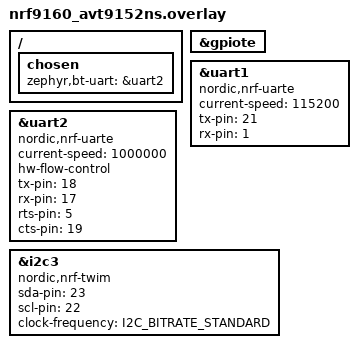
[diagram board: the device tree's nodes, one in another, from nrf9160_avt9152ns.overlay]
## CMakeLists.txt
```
#
# Copyright (c) 2019 Nordic Semiconductor
#
# SPDX-License-Identifier: LicenseRef-BSD-5-Clause-Nordic
#

cmake_minimum_required(VERSION 3.13.1)

list(APPEND mcuboot_OVERLAY_CONFIG
  "${CMAKE_CURRENT_SOURCE_DIR}/child_mcuboot.conf"
  )

set(spm_CONF_FILE
  prj.conf
  ${CMAKE_CURRENT_SOURCE_DIR}/child_secure_partition_manager.conf
  )

find_package(Zephyr REQUIRED HINTS $ENV{ZEPHYR_BASE})
project(demo_IoTConnect)



# NORDIC SDK APP START
target_sources(app PRIVATE src/main.c)
target_sources(app PRIVATE src/slm_at_host.c)
target_sources(app PRIVATE src/slm_util.c)
target_sources(app PRIVATE src/slm_at_gps.c)
target_sources(app PRIVATE src/orientation_tap_detector.c)
target_sources(app PRIVATE src/pir_detector.c)
target_sources(app PRIVATE src/rotation_detector.c)
target_sources(app PRIVATE src/env_sensors.c)
target_sources(app PRIVATE src/gps.c)
zephyr_library_sources_ifdef(CONFIG_SUPL_CLIENT_LIB src/supl_support.c)

target_link_libraries(app PRIVATE ${CMAKE_CURRENT_SOURCE_DIR}/IoTConnect/libiotconnect.a)

zephyr_include_directories(IoTConnect)
# NORDIC SDK APP END
```

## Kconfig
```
#
# Copyright (c) 2019 Nordic Semiconductor
#
# SPDX-License-Identifier: LicenseRef-BSD-5-Clause-Nordic
#

menu "Demo IoTConnect"

config DEMO_AT_MAX_PARAM
	int "Max number of parameters in AT command"
	default 8
	
config DEMO_ENVIRONMENT_DATA_SEND_INTERVAL
	int "Interval in seconds for sending environment data"
	default 60
	help
	  How often to send environment sensor data.
	  If the GPS is active, sensor data will not be sent before it is
	  stopped. The unit is seconds.


#
# A-GPS
#
config DEMO_SUPL_SERVER
	string "SUPL server"
	default "supl.google.com"

config DEMO_SUPL_SERVER_PORT
	int "SUPL server port"
	default 7276

module = DEMO_IOTCONNECT
module-str = demo
source "${ZEPHYR_BASE}/subsys/logging/Kconfig.template.log_config"

endmenu

menu "Zephyr Kernel"
source "Kconfig.zephyr"
endmenu
```

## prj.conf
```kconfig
# Demo IoTConnect

CONFIG_DEMO_IOTCONNECT_LOG_LEVEL_DBG=y
CONFIG_MCUBOOT_IMAGE_VERSION="1.0.2"

#<major>*1000000 + <minor>*1000 + <build>
CONFIG_FW_INFO_FIRMWARE_VERSION=1000002

# Stacks and heaps
CONFIG_MAIN_STACK_SIZE=8192
CONFIG_HEAP_MEM_POOL_SIZE=16384
CONFIG_SYSTEM_WORKQUEUE_STACK_SIZE=2048


# Device power management
CONFIG_DEVICE_POWER_MANAGEMENT=y

# Sensors I2C
CONFIG_I2C=y
CONFIG_I2C_NRFX=y

# UART for slm_at_host
CONFIG_UART_NRFX=y
CONFIG_NRFX_UARTE=y
CONFIG_NRFX_UARTE0=y
CONFIG_UART_0_INTERRUPT_DRIVEN=n
CONFIG_UART_ASYNC_API=y
CONFIG_UART_0_ASYNC=y
CONFIG_UART_0_NRF_HW_ASYNC=y
CONFIG_UART_0_NRF_HW_ASYNC_TIMER=1
CONFIG_NRFX_TIMER=y
CONFIG_NRFX_TIMER1=y

# C Library
CONFIG_NEWLIB_LIBC=y
CONFIG_NEWLIB_LIBC_FLOAT_PRINTF=y

# File Systems
CONFIG_NVS=y
CONFIG_PM_PARTITION_SIZE_NVS_STORAGE=0x4000
CONFIG_MPU_ALLOW_FLASH_WRITE=y
CONFIG_NVS_LOG_LEVEL_OFF=y

# Debugging Options
CONFIG_ASSERT=y
#CONFIG_DEBUG_OPTIMIZATIONS=y

# Logging
CONFIG_LOG=y
CONFIG_LOG_PRINTK=y
CONFIG_LOG_IMMEDIATE=y
#CONFIG_LOG_BUFFER_SIZE=4096


# Networking
CONFIG_NETWORKING=y
CONFIG_NET_NATIVE=n
CONFIG_NET_SOCKETS=y
CONFIG_NET_SOCKETS_OFFLOAD=y # using \nrf\lib\bsdlib\nrf91_sockets.c

# BSD Library for nrf91
CONFIG_BSD_LIBRARY=y
CONFIG_BSD_LIBRARY_TRACE_ENABLED=n

# AT Command driver
CONFIG_AT_CMD=y                   # needed by slm_at_host

CONFIG_AT_NOTIF=y                 # needed by slm_at_host
CONFIG_AT_CMD_PARSER=y            # needed by slm_at_host

CONFIG_SUPL_CLIENT_LIB=y          # needed for aGPS


# Modem key management
CONFIG_MODEM_KEY_MGMT=y

# LTE link control
CONFIG_LTE_LINK_CONTROL=y
CONFIG_LTE_AUTO_INIT_AND_CONNECT=n
CONFIG_LTE_NETWORK_MODE_LTE_M_GPS=y         # doesnt matter as lte network to use will be based on setting stored in nvs
CONFIG_LTE_LEGACY_PCO_MODE=y                # extended PCO may not be supported by the network
CONFIG_LTE_NETWORK_USE_FALLBACK=n
#CONFIG_LTE_LINK_CONTROL_LOG_LEVEL_DBG=y

# MQTT
CONFIG_MQTT_LIB=y
CONFIG_MQTT_LIB_TLS=y

# External libraries
CONFIG_CJSON_LIB=y

# add fota support
CONFIG_BOOTLOADER_MCUBOOT=y       # to enable mcuboot
CONFIG_REBOOT=y                   # to enable sys_reboot() to be able to automatically reset to boot to the updated image
CONFIG_FOTA_DOWNLOAD=y            # to include FOTA library
CONFIG_FOTA_DOWNLOAD_PROGRESS_EVT=y # for the caller to be updated of download progress
CONFIG_DOWNLOAD_CLIENT=y          # needed by FOTA_DOWNLOAD
#CONFIG_DOWNLOAD_CLIENT_LOG_LEVEL_DBG=y
CONFIG_DFU_TARGET=y               # needed by FOTA_DOWNLOAD
CONFIG_DFU_TARGET_MODEM=y         # enabled by default with DFU_TARGET=y
CONFIG_DFU_TARGET_MCUBOOT=y       # enabled by default with DFU_TARGET=y given all needed modules are enabled
CONFIG_IMG_MANAGER=y              # needed by DFU_TARGET_MCUBOOT
CONFIG_IMG_ERASE_PROGRESSIVELY=y  # needed by DFU_TARGET_MCUBOOT
CONFIG_MCUBOOT_IMG_MANAGER=y      # enabled by IMG_MANAGER=y
CONFIG_FLASH_MAP=y                # needed by MCUBOOT_IMG_MANAGER
CONFIG_FLASH=y                    # needed by FLASH_MAP for FLASH_HAS_DRIVER_ENABLED

# copy config from http_application_update example
CONFIG_DOWNLOAD_CLIENT_STACK_SIZE=4096

# <account>.blob.core.windows.net is closing the connection without responding on https GET partial request of 2kB
CONFIG_DOWNLOAD_CLIENT_HTTP_FRAG_SIZE_1024=y

# copy config from azure_fota example
CONFIG_DOWNLOAD_CLIENT_BUF_SIZE=2300

# Enable Bluetooth stack and libraries
CONFIG_BT=y
#CONFIG_BT_DEBUG_LOG=y
CONFIG_BT_DEVICE_NAME="AVT9152"
CONFIG_BT_H4=y
#CONFIG_BT_UART_ON_DEV_NAME="UART_2" is set through board files with chosen { zephyr,bt-uart=&uart2; }
CONFIG_BT_WAIT_NOP=y
CONFIG_BT_BROADCASTER=y
#CONFIG_UART_2_NRF_UARTE=y is set through board files with &uart2 { compatible = "nordic,nrf-uarte"; }
CONFIG_UART_2_INTERRUPT_DRIVEN=y
#CONFIG_UART_2_NRF_FLOW_CONTROL=y is set through board files with &uart2 { hw-flow-control; }
CONFIG_BT_HCI_VS=y
```

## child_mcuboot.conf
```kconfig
#
# Copyright (c) 2020 Nordic Semiconductor ASA
#
# SPDX-License-Identifier: LicenseRef-BSD-5-Clause-Nordic
#

CONFIG_USE_SEGGER_RTT=y
CONFIG_RTT_CONSOLE=y
CONFIG_UART_CONSOLE=n

CONFIG_SIZE_OPTIMIZATIONS=y

# MCUBoot settings
CONFIG_BOOT_MAX_IMG_SECTORS=256

# MCUboot serial recovery
CONFIG_MCUBOOT_SERIAL=y
CONFIG_BOOT_SERIAL_DETECT_PORT="GPIO_0"
CONFIG_BOOT_SERIAL_DETECT_PIN=21
CONFIG_BOOT_SERIAL_DETECT_PIN_VAL=0

CONFIG_BOOT_SIGNATURE_TYPE_RSA=y
CONFIG_BOOT_SIGNATURE_KEY_FILE="root-rsa-2048.pem"
```

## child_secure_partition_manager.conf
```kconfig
#
# Copyright (c) 2019 Nordic Semiconductor ASA
#
# SPDX-License-Identifier: LicenseRef-BSD-5-Clause-Nordic
#

# Set UARTE2 as non-secure, used for bluetooth controller
CONFIG_SPM_NRF_UARTE2_NS=y

# Set REGULATORS as non-secure, used for sleep/wakeup
CONFIG_SPM_NRF_REGULATORS_NS=y

# Enable below for power saving
CONFIG_SERIAL=n
CONFIG_CONSOLE=n
CONFIG_UART_CONSOLE=n
CONFIG_LOG=n
CONFIG_LOG_BACKEND_UART=n
```

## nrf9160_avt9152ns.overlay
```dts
/* SPDX-License-Identifier: Apache-2.0 */

/ {
	chosen {
		zephyr,bt-uart = &uart2;
	};
};

&gpiote {
	status = "okay";
};

&uart1 {
	compatible = "nordic,nrf-uarte";
	current-speed = <115200>;
	status = "okay";
	tx-pin = <21>;
	rx-pin = <1>; 
};

&uart2 {
	compatible = "nordic,nrf-uarte";
	current-speed = <1000000>;
	hw-flow-control;
	status = "okay";
	tx-pin = <18>;
	rx-pin = <17>;
	rts-pin = <5>;
	cts-pin = <19>;
};

&i2c3 {
	compatible = "nordic,nrf-twim";
	status = "okay";
	sda-pin = <23>;
	scl-pin = <22>;
	clock-frequency = <I2C_BITRATE_STANDARD>;
};
```

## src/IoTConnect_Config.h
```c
#ifndef IOTCONNECT_CONFIG_H
#define IOTCONNECT_CONFIG_H

#define CONFIG_IOTCONNECT_DISCOVERY_SEC_TAG         623
#define CONFIG_IOTCONNECT_MQTT_SEC_TAG              624

#define CONFIG_IOTCONNECT_POLL_TIMEOUT_MS           500

#define CONFIG_IOTCONNECT_SYSTEM_TIME_UPDATE        (60 * 60)  // in seconds

/* IoTConnect credential configuration */

/* comment out CONFIG_IOTCONNECT_DEVICE_UNIQUE_ID to use device IMEI as its unique id */
#if 0
#define CONFIG_IOTCONNECT_DEVICE_UNIQUE_ID          "avt9152testdev0001"
#endif
#define CONFIG_IOTCONNECT_DEVICE_CP_ID              "149847e8f3ab4f11a90878bfa7da9922"
#define CONFIG_IOTCONNECT_DEVICE_ENV                "avnet"


#endif /* IOTCONNECT_CONFIG_H */
```

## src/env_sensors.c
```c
/*
 * Copyright (c) 2020 Avnet Asia Pte. Ltd.
 *
 * SPDX-License-Identifier: LicenseRef-BSD-3-Clause
 */

#include <zephyr.h>
#include <device.h>
#include <drivers/i2c.h>
#include "env_sensors_regs.h"
#include "env_sensors.h"


#define SENSORS_TASK_STACK_SIZE     KB(1)
#define SENSORS_TASK_PRIORITY       K_LOWEST_APPLICATION_THREAD_PRIO


#define SENSORS_DATA_UPDATE_INTERVAL_S      1

#include <logging/log.h>
LOG_MODULE_REGISTER(env_sensors, LOG_LEVEL_INF);


K_THREAD_STACK_DEFINE(sensors_task_stack_area, SENSORS_TASK_STACK_SIZE);
K_SEM_DEFINE(m_sens_data_sem, 1, 1);
K_SEM_DEFINE(m_evt_data_sem, 1, 1);

struct k_thread sensors_task_thread_data;
k_tid_t m_sensors_task_tid;

static const struct device *sensors_i2c_dev = NULL;
static env_sensors_data_t m_sens_data;
static bool m_task_stop;
static bool m_task_stopped;


static bool i2c_read_reg(const struct device *dev, uint8_t slave_addr, uint8_t reg, uint8_t *p_reg_val){

    struct i2c_msg msgs[2];

    msgs[0].buf = &reg;
    msgs[0].len = 1U;
    msgs[0].flags = I2C_MSG_WRITE;

    msgs[1].buf = p_reg_val;
    msgs[1].len = 1U;
    msgs[1].flags = I2C_MSG_READ | I2C_MSG_STOP;

    return i2c_transfer(dev, msgs, 2, slave_addr);
}

static bool i2c_read_regs(const struct device *dev, uint8_t slave_addr, uint8_t start_reg, uint8_t *p_reg_vals, uint32_t regs_to_read){

    struct i2c_msg msgs[2];

    msgs[0].buf = &start_reg;
    msgs[0].len = 1U;
    msgs[0].flags = I2C_MSG_WRITE;

    msgs[1].buf = p_reg_vals;
    msgs[1].len = regs_to_read;
    msgs[1].flags = I2C_MSG_READ | I2C_MSG_STOP;

    return i2c_transfer(dev, msgs, 2, slave_addr);
}

static int i2c_write_reg(const struct device *dev, uint8_t slave_addr, uint8_t reg, uint8_t reg_val){

    struct i2c_msg msgs[1];
    uint8_t payload[2];

    payload[0] = reg;
    payload[1] = reg_val;

    msgs[0].buf = payload;
    msgs[0].len = 2U;
    msgs[0].flags = I2C_MSG_WRITE | I2C_MSG_STOP;

    return i2c_transfer(dev, msgs, 1, slave_addr);
}

static void reset_sensors_data(){

    m_sens_data.pressure = 0.0;
    m_sens_data.temperature = 0.0;
    m_sens_data.humidity = 0.0;
    m_sens_data.illumination = 0;
}

static void read_sensors_data(){
    
    int err_code;
    uint8_t rx[5];
    env_sensors_data_t sd;

    memset(&sd, 0, sizeof(sd));
     
    /* Read Pressure and temperature */
    // trigger one-shot 
    err_code = i2c_write_reg(sensors_i2c_dev, LPS22HB_7BIT_ADDR, LPS22HB_REG_CTRL2, LPS22HB_REG_CTRL2_ONE_SHOT | LPS22HB_REG_CTRL2_ADD_INC_EN);
    if (err_code != 0){
        LOG_ERR("U4 LPS22HB Pressure+Temp ONE_SHOT failed 0x%0x.", err_code);
        goto read_TE_2314277_1;
    }
    do
    {
        err_code = i2c_read_reg(sensors_i2c_dev, LPS22HB_7BIT_ADDR, LPS22HB_REG_CTRL2, &rx[0]);
        if (err_code != 0){
            LOG_ERR("U4 LPS22HB Pressure+Temp read CTRL2 failed 0x%0x.", err_code);
            goto read_TE_2314277_1;
        }
    } while ((rx[0] & LPS22HB_REG_CTRL2_ONE_SHOT) != 0);

    // status register T_DA=1 P_DA=1
    err_code = i2c_read_reg(sensors_i2c_dev, LPS22HB_7BIT_ADDR, LPS22HB_REG_STATUS, &rx[0]);
    if (err_code != 0){
        LOG_ERR("U4 LPS22HB Pressure+Temp read STATUS failed 0x%0x.", err_code);
        goto read_TE_2314277_1;
    }
    if ((rx[0] & 0x03) != 0x03){
        LOG_ERR("U4 LPS22HB Pressure+Temp T_DA & P_DA expected to be set.");
        goto read_TE_2314277_1;
    }

    // read data
    err_code = i2c_read_regs(sensors_i2c_dev, LPS22HB_7BIT_ADDR, LPS22HB_REG_PRESS_OUT_XL, rx, 5);
    if (err_code != 0){
        LOG_ERR("U4 LPS22HB Pressure+Temp read data failed 0x%0x.", err_code);
        goto read_TE_2314277_1;
    }
    {
        uint32_t pres;
        uint16_t temp;
        pres = ((uint32_t) rx[0]) |
               (((uint32_t) rx[1]) << 8) |
               (((uint32_t) rx[2]) << 16);
        pres <<= 8;
        temp = ((uint16_t) rx[3]) |
               (((uint16_t) rx[4]) << 8);
        // Dividing by 256 because signed integer can't be shifted by 8
        sd.pressure    = *((int32_t *) &pres) / 256.0 / 4096.0;
        sd.temperature = *((int16_t *) &temp) / 100.0;
    }
    
read_TE_2314277_1:

    /* Read humidity and illuminiation */

    err_code = i2c_write_reg(sensors_i2c_dev, TE_2314277_1_7BIT_ADDR, TE_2314277_1_REG_SCAN_START_BYTE,
                            TE_2314277_1_REG_SCAN_HUMIDITY_BITMASK | TE_2314277_1_REG_SCAN_LIGHT_BITMASK);
    if (err_code != 0){
        LOG_ERR("U5 2314277-1 Ambimate write SCAN_START_BYTE failed 0x%0x.", err_code);
        return;
    }
    // wait until measurement is complete
    do {
        k_sleep(SYS_TIMEOUT_MS(10));
        err_code = i2c_read_reg(sensors_i2c_dev, TE_2314277_1_7BIT_ADDR, TE_2314277_1_REG_SCAN_START_BYTE, &rx[0]);
    } while ((err_code == 0) && (rx[0] > 0));
    if (err_code != 0){
        LOG_ERR("U5 2314277-1 Ambimate read SCAN_START_BYTE failed 0x%0x.", err_code);
        return;
    }
    err_code = i2c_read_regs(sensors_i2c_dev, TE_2314277_1_7BIT_ADDR, TE_2314277_1_REG_HUMIDITY_H, rx, 4);
    if (err_code != 0){
        LOG_ERR("U5 2314277-1 Ambimate read measurement data failed 0x%0x.", err_code);
        return;
    }

    // convert the raw data to engineering units
    sd.humidity = (rx[0] * 256.0 + rx[1]) / 10.0;
    sd.illumination = (rx[2] * 256 + rx[3]);

    //transfer
    k_sem_take(&m_sens_data_sem, SYS_TIMEOUT_MS(SYS_FOREVER_MS));
    memcpy(&m_sens_data, &sd, sizeof(env_sensors_data_t));
    k_sem_give(&m_sens_data_sem);

}

static void sensors_task(void *p1, void *p2, void *p3){

    m_task_stopped = false;

    LOG_DBG(">>");

    reset_sensors_data();

    while(!m_task_stop){

        read_sensors_data();

        k_sleep(SYS_TIMEOUT_MS(SENSORS_DATA_UPDATE_INTERVAL_S * MSEC_PER_SEC));

    }
    
    m_task_stopped = true;

    LOG_DBG("<<");
}

bool env_sensors_start(void){

    if(!m_task_stopped){
        return false;
    }
    
    m_task_stop = false;

    m_sensors_task_tid = k_thread_create(&sensors_task_thread_data, sensors_task_stack_area,
                                 K_THREAD_STACK_SIZEOF(sensors_task_stack_area),
                                 sensors_task,
                                 NULL, NULL, NULL,
                                 SENSORS_TASK_PRIORITY, 0, K_NO_WAIT);

    return true;
}

bool env_sensors_stop(void){

    uint32_t start_time;

    m_task_stop = true;

    start_time = k_uptime_get_32();

    while(m_task_stopped == false && (k_uptime_get_32() - start_time) < 2000){
        k_sleep(SYS_TIMEOUT_MS(10));
    }

    if(m_task_stopped == false){
        LOG_DBG("Sensors task fail to terminate itself. Force task abort!"); 
        k_thread_abort(m_sensors_task_tid);
        m_task_stopped = true;
    }

    m_task_stop = false;
    return true;
}

bool env_sensors_is_running(void){

    return !m_task_stopped;

}


#define SENS_I2C_NODE       DT_ALIAS(sens_i2c)
bool env_sensors_init(void){
    
    uint8_t reg_val;

    if(sensors_i2c_dev == NULL){
        sensors_i2c_dev = device_get_binding(DT_LABEL(SENS_I2C_NODE));
    
        if(sensors_i2c_dev == NULL){
            LOG_ERR("Unable to bind device %s.", DT_LABEL(DT_ALIAS(sens_i2c)));
            return false;
        }

        /************************************/
        /* Test LPS22HB I2C communication */
        /************************************/
        //Read LPS22HB WHO_AM_I registers
        reg_val = 0xff;
        if(i2c_read_reg(sensors_i2c_dev, LPS22HB_7BIT_ADDR, LPS22HB_REG_WHO_AM_I, &reg_val)==0){
            if(reg_val != LPS22HB_WHO_AM_I){
                LOG_ERR("Read LPS22HB sensor NOT OK. Expected value %d but received %d.",
                        LPS22HB_WHO_AM_I, reg_val);
                return false;
            }
        }else{
            LOG_ERR("Read LPS22HB sensor fail.");
            return false;
        }

        /************************************/
        /* Test 2314277_1 I2C communication */
        /************************************/
        //Read 2314277_1 OPTIONS registers
        if(i2c_read_reg(sensors_i2c_dev, TE_2314277_1_7BIT_ADDR, TE_2314277_1_REG_OPTIONAL_SENSORS, &reg_val)!=0){
            LOG_ERR("Read 2314277_1 sensor fail.");
            return false;
        }

        reset_sensors_data();

        m_task_stop = false;
        m_task_stopped = true;

    }
    return true;
}

void env_sensors_uninit(){

    sensors_i2c_dev = NULL;
}

bool env_sensors_get_data(env_sensors_data_t *p_sens_data){

    if(sensors_i2c_dev == NULL){
        return false;
    }
    k_sem_take(&m_sens_data_sem, SYS_TIMEOUT_MS(SYS_FOREVER_MS));

    memcpy(p_sens_data, &m_sens_data, sizeof(env_sensors_data_t));

    k_sem_give(&m_sens_data_sem);

    return true;
}
```

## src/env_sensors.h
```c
/*
 * Copyright (c) 2020 Avnet Asia Pte. Ltd.
 *
 * SPDX-License-Identifier: LicenseRef-BSD-3-Clause
 */
 
#ifndef ENV_SENSORS_H
#define ENV_SENSORS_H

typedef struct {

    float pressure;
    float temperature;
    float humidity;
    uint16_t illumination;

} env_sensors_data_t;


bool env_sensors_init(void);
void env_sensors_uninit(void);
bool env_sensors_start(void);
bool env_sensors_stop(void);
bool env_sensors_is_running(void);
bool env_sensors_get_data(env_sensors_data_t *p_sens_data);


#endif // ENV_SENSORS_H
```

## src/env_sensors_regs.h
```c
#ifndef ENV_SENSORS_REGS_H
#define ENV_SENSORS_REGS_H


//U4 LPS22HBTR 24bit-Pressure, 16bit-Temperature Sensor (7bit address 0x5D) WHO_AM_I = 0xB1
#define LPS22HB_7BIT_ADDR                   0x5D
#define LPS22HB_REG_WHO_AM_I                0x0F
#define LPS22HB_REG_CTRL1                   0x10
#define LPS22HB_REG_CTRL2                   0x11
#define LPS22HB_REG_CTRL3                   0x12
#define LPS22HB_REG_STATUS                  0x27
#define LPS22HB_REG_PRESS_OUT_XL            0x28
#define LPS22HB_REG_PRESS_OUT_L             0x29
#define LPS22HB_REG_PRESS_OUT_H             0x2A
#define LPS22HB_REG_TEMP_OUT_L              0x2B
#define LPS22HB_REG_TEMP_OUT_H              0x2C

#define LPS22HB_WHO_AM_I                    0xB1

#define LPS22HB_REG_CTRL2_ONE_SHOT          BIT(0)
#define LPS22HB_REG_CTRL2_SWRESET           BIT(2)
#define LPS22HB_REG_CTRL2_ADD_INC_EN        BIT(4) // Register address automatically incremented during a multiple byte access with a serial interface (I2C or SPI). Default value: 1 (0: disable; 1 enable)
#define LPS22HB_REG_CTRL3_INT_ACTIVE_LOW    BIT(7) // Interrupt active-high/low. Default value: 0 (0: active high; 1: active low)
#define LPS22HB_REG_CTRL3_DRDY_EN           BIT(2) // Data-ready signal on INT_DRDY pin. Default value: 0 (0: disable; 1: enable)

// U5 2314277-1 Ambimate (Humidity, Light, Motion, Temperature) Sensor (7bit address: 0x2A) Optional Sensors = 0x00
#define TE_2314277_1_7BIT_ADDR              0x2A

#define TE_2314277_1_REG_STATUS             0x00
#define TE_2314277_1_REG_TEMPERATURE_H      0x01
#define TE_2314277_1_REG_TEMPERATURE_L      0x02
#define TE_2314277_1_REG_HUMIDITY_H         0x03
#define TE_2314277_1_REG_HUMIDITY_L         0x04
#define TE_2314277_1_REG_LIGHT_H            0x05
#define TE_2314277_1_REG_LIGHT_LOW          0x06
#define TE_2314277_1_REG_AUDIO_H            0x07
#define TE_2314277_1_REG_AUDIO_L            0x08
#define TE_2314277_1_REG_BATTERY_VOLTS_H    0x09
#define TE_2314277_1_REG_BATTERY_VOLTS_L    0x0A

#define TE_2314277_1_REG_FIRMWARE_VERSION     0x80
#define TE_2314277_1_REG_FIRMWARE_SUBVERSION  0x81
#define TE_2314277_1_REG_OPTIONAL_SENSORS     0x82

#define TE_2314277_1_REG_SCAN_START_BYTE      0xC0
#define TE_2314277_1_REG_RESET                0xF0

#define TE_2314277_1_RESET                    0xA5

#define TE_2314277_1_OPTIONAL_SENSORS_NONE    0x00
#define TE_2314277_1_OPTIONAL_CO2_BITMASK     BIT(0)
#define TE_2314277_1_OPTIONAL_MIC_BITMASK     BIT(2)

#define TE_2314277_1_REG_SCAN_STATUS_BITMASK    BIT(0)
#define TE_2314277_1_REG_SCAN_TEMP_BITMASK      BIT(1)
#define TE_2314277_1_REG_SCAN_HUMIDITY_BITMASK  BIT(2)
#define TE_2314277_1_REG_SCAN_LIGHT_BITMASK     BIT(3)
#define TE_2314277_1_REG_SCAN_AUDIO_BITMASK     BIT(4)
#define TE_2314277_1_REG_SCAN_BATT_BITMASK      BIT(5)
#define TE_2314277_1_REG_SCAN_GAS_BITMASK       BIT(6)

#define TE_2314277_1_REG_STATUS_MOTION_EVT_BITMASK  BIT(0)
#define TE_2314277_1_REG_STATUS_AUDIO_EVT_BITMASK   BIT(1)
#define TE_2314277_1_REG_STATUS_PIR_EVT_BITMASK     BIT(7)


#endif // ENV_SENSORS_REGS_H
```

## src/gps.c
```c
/*
 * Copyright (c) 2019 Nordic Semiconductor ASA
 *
 * SPDX-License-Identifier: LicenseRef-BSD-5-Clause-Nordic
 */

#include <zephyr.h>
#include <stdio.h>
#include <stdlib.h>
#include <string.h>
#include <strings.h>
#include <ctype.h>
#include <device.h>
#include <sys_clock.h>
#include <nrf_socket.h>
#include <net/socket.h>
#include <modem/at_cmd.h>
#include <bsd.h>
#ifdef CONFIG_SUPL_CLIENT_LIB
#include <modem/lte_lc.h>
#include <supl_os_client.h>
#include <supl_session.h>
#include "supl_support.h"
#endif
#include "gps.h"

#include <logging/log.h>
LOG_MODULE_REGISTER(app_gps, LOG_LEVEL_DBG);

#define GPS_PROCESS_STACK_SIZE  KB(4)
#define GPS_PROCESS_PRIORITY    K_LOWEST_APPLICATION_THREAD_PRIO

K_THREAD_STACK_DEFINE(gps_process_stack_area, GPS_PROCESS_STACK_SIZE);

struct k_thread gps_process_thread_data;
k_tid_t gps_process_tid = NULL;

static int gnss_fd = -1;
nrf_gnss_data_frame_t gps_data;
nrf_gnss_data_frame_t last_fix;
static bool got_first_fix = false;
static bool m_gps_process_stop = true;
static bool m_gps_process_stopped = true;
static bool agps_data_request = false;
static bool gps_started = false;

static int process_gps_data()
{
    int retval;

    retval = nrf_recv(gnss_fd,
              &gps_data,
              sizeof(nrf_gnss_data_frame_t),
              NRF_MSG_DONTWAIT);

    if (retval > 0) {

        switch (gps_data.data_id) {
        case NRF_GNSS_PVT_DATA_ID:

            if ((gps_data.pvt.flags &
                NRF_GNSS_PVT_FLAG_FIX_VALID_BIT)
                == NRF_GNSS_PVT_FLAG_FIX_VALID_BIT) {

                if (!got_first_fix) {
                    got_first_fix = true;
                }

                memcpy(&last_fix,
                       &gps_data,
                       sizeof(nrf_gnss_data_frame_t));

            }
            break;

        case NRF_GNSS_NMEA_DATA_ID:
            break;
        case NRF_GNSS_AGPS_DATA_ID:
            agps_data_request = true;
            return 0;
            break;

        default:
            break;
        }
    }

    return retval;
}

#ifdef CONFIG_SUPL_CLIENT_LIB
int inject_agps_type(void *agps,
             size_t agps_size,
             nrf_gnss_agps_data_type_t type,
             void *user_data)
{
    ARG_UNUSED(user_data);
    int retval = nrf_sendto(gnss_fd,
                agps,
                agps_size,
                0,
                &type,
                sizeof(type));

    if (retval != 0) {
        LOG_ERR("Failed to send AGNSS data, type: %d (err: %d)",
               type,
               errno);
        return -1;
    }

    LOG_INF("Injected AGPS data, flags: %d, size: %d", type, agps_size);

    return 0;
}
#endif

static bool gps_open(int gps_fd){

    int retval;
    nrf_gnss_fix_retry_t    fix_retry    = 0;
    nrf_gnss_fix_interval_t fix_interval = 1;
    nrf_gnss_delete_mask_t  delete_mask  = 0;
    nrf_gnss_nmea_mask_t    nmea_mask    = 0;

    retval = nrf_setsockopt(gps_fd,
                NRF_SOL_GNSS,
                NRF_SO_GNSS_FIX_RETRY,
                &fix_retry,
                sizeof(fix_retry));

    if (retval != 0) {
        LOG_ERR("ERR: Failed to set fix retry value");
        //nrf_close(gnss_fd);
        //gnss_fd = -1;
        return false;
    }

    retval = nrf_setsockopt(gps_fd,
                NRF_SOL_GNSS,
                NRF_SO_GNSS_FIX_INTERVAL,
                &fix_interval,
                sizeof(fix_interval));

    if (retval != 0) {
        LOG_ERR("ERR: Failed to set fix interval value");
        return false;
    }

    retval = nrf_setsockopt(gps_fd,
                NRF_SOL_GNSS,
                NRF_SO_GNSS_NMEA_MASK,
                &nmea_mask,
                sizeof(nmea_mask));

    if (retval != 0) {
        LOG_ERR("ERR: Failed to set nmea mask");
        //nrf_close(gnss_fd);
        //gnss_fd = -1;
        return -1;
    }

    retval = nrf_setsockopt(gps_fd,
                NRF_SOL_GNSS,
                NRF_SO_GNSS_START,
                &delete_mask,
                sizeof(delete_mask));

    if (retval != 0) {
        LOG_ERR("ERR: Failed to start GPS");
        //nrf_close(gnss_fd);
        //gnss_fd = -1;
        return false;
    }

    gps_started = true;
    got_first_fix = false;
    agps_data_request = false;
    
    return true;
}

static bool gps_close(int gps_fd){

    int retval;
    nrf_gnss_delete_mask_t  delete_mask  = 0;


    retval = nrf_setsockopt(gps_fd,
                NRF_SOL_GNSS,
                NRF_SO_GNSS_STOP,
                &delete_mask,
                sizeof(delete_mask));

    if (retval != 0) {
        LOG_ERR("ERR: Failed to stop GPS");
        return false;
    }
    gps_started = false;
    return true;
}

static void gps_process(void *p1, void *p2, void *p3){

    m_gps_process_stop = false;
    m_gps_process_stopped = false;

    LOG_DBG("START");

    while(m_gps_process_stop == false){

        do {
            /* Loop until we don't have more
             * data to read
             */
        } while (process_gps_data() > 0);

#ifdef CONFIG_SUPL_CLIENT_LIB
        if(agps_data_request){
            agps_data_request = false;
            LOG_INF("New AGPS data requested, contacting SUPL server, flags %d",
                   gps_data.agps.data_flags);
            gps_close(gnss_fd);
      if (open_supl_socket() == 0) {
          LOG_INF("Starting SUPL session");
          supl_session(&gps_data.agps);
          LOG_INF("Done");
          close_supl_socket();
      }
            gps_open(gnss_fd);
            k_sleep(SYS_TIMEOUT_MS(2000));
        }
#endif

        k_sleep(SYS_TIMEOUT_MS(500));

    }

    m_gps_process_stopped = true;

}

#define AT_MAGPIO           "AT\%XMAGPIO=1,0,0,1,1,1574,1577"//"AT\%XMAGPIO"
#define CME_ERR_GPS_NOT_FIX             516


bool gps_start(void){

    if(!gps_started){

        gnss_fd = nrf_socket(NRF_AF_LOCAL, NRF_SOCK_DGRAM, NRF_PROTO_GNSS);

        if (gnss_fd < 0) {
            LOG_ERR("ERR: Could not init socket (err: %d)", gnss_fd);
            return false;
        }

        if(gps_open(gnss_fd) == false){
            return false;
        }

        gps_process_tid = k_thread_create(&gps_process_thread_data, gps_process_stack_area,
                                     K_THREAD_STACK_SIZEOF(gps_process_stack_area),
                                     gps_process,
                                     NULL, NULL, NULL,
                                     GPS_PROCESS_PRIORITY, 0, K_NO_WAIT);

    }else{
        return false;
    }
    return true;
}

bool gps_stop(){
    
    int retval;
    uint32_t start_time;
    
    if(gps_started && m_gps_process_stopped == false){

        m_gps_process_stop = true;

        start_time = k_uptime_get_32();

        while(m_gps_process_stopped == false && (k_uptime_get_32() - start_time) < 2000){
            k_sleep(SYS_TIMEOUT_MS(10));
        }
        //k_thread_abort(gps_process_tid);
        if(m_gps_process_stopped == false){
            LOG_ERR("ERR: GPS process task fail to terminate itself. Force task abort!"); 
            k_thread_abort(gps_process_tid);
            m_gps_process_stopped = true;
        }

        if(gps_close(gnss_fd)==false){
            return false;
        }

        retval = nrf_close(gnss_fd);

        if (retval != 0) {
            LOG_ERR("ERR: Failed to close socket! (err: %d)", retval);
            return false;
        }

        gnss_fd = -1;
        return true;

    }else{

        return false;
    }
}

bool gps_init(void){

    const char at_commands[][31]  = { AT_MAGPIO };
    enum at_cmd_state state;
#ifdef CONFIG_SUPL_CLIENT_LIB
    static struct supl_api supl_api = {
        .read       = supl_recv,
        .write      = supl_send,
        .handler    = inject_agps_type,
        .logger     = supl_log,
        .counter_ms = k_uptime_get
    };
#endif

    for(int i=0; i<ARRAY_SIZE(at_commands); i++){
        if (at_cmd_write(at_commands[i], NULL, 0, &state) != 0) {
            LOG_ERR("ERR: Fail to send %s", at_commands[i]);
            return false;
        }
        if(state != AT_CMD_OK){
            LOG_ERR("[ERR: %s returns error!", at_commands[i]);
            return false;
        }
    }
#ifdef CONFIG_SUPL_CLIENT_LIB
    int rc = supl_init(&supl_api);

    if (rc != 0) {
        return false;
    }
#endif
    gps_started = false;
    return true;
}

bool gps_is_active(void){

    return gps_started;
}

bool gps_acquire_loc(float *p_latitude, float *p_longitude){

    if(!gps_started){
        return false;
    }
    if(got_first_fix){
        *p_latitude = last_fix.pvt.latitude;
        *p_longitude = last_fix.pvt.longitude;
        return true;
    }
    return false;
}

bool gps_acquire_latest_pvt_data(nrf_gnss_pvt_data_frame_t *p_pvt){

    if(!gps_started){
        return false;
    }

    if(got_first_fix){
        memcpy(p_pvt, &last_fix.pvt, sizeof(nrf_gnss_pvt_data_frame_t));
        return true;
    }

    return false;
}
```

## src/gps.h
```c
#ifndef GPS_H
#define GPS_H

#include <nrf_socket.h>

bool gps_init(void);
bool gps_start(void);
bool gps_stop(void);
bool gps_is_active(void);
bool gps_acquire_loc(float *p_latitude, float *p_longitude);
bool gps_acquire_latest_pvt_data(nrf_gnss_pvt_data_frame_t *p_pvt);


#endif
```

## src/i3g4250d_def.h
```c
#ifndef I3G4250D_DEF_H_
#define I3G4250D_DEF_H_


#define I3G4250D_7BIT_ADDR                  0x69
#define I3G4250D_REG_WHO_AM_I               0x0F
#define I3G4250D_REG_CTRL_REG1              0x20
#define I3G4250D_REG_CTRL_REG2              0x21
#define I3G4250D_REG_CTRL_REG3              0x22
#define I3G4250D_REG_CTRL_REG4              0x23
#define I3G4250D_REG_CTRL_REG5              0x24
#define I3G4250D_REG_REFERENCE              0x25
#define I3G4250D_REG_STATUS_REG             0x27
#define I3G4250D_REG_OUT_X_L                0x28
#define I3G4250D_REG_OUT_X_H                0x29
#define I3G4250D_REG_OUT_Y_L                0x2A
#define I3G4250D_REG_OUT_Y_H                0x2B
#define I3G4250D_REG_OUT_Z_L                0x2C
#define I3G4250D_REG_FIFO_CTRL_REG          0x2E
#define I3G4250D_REG_FIFO_SRC_REG           0x2F
#define I3G4250D_REG_INT1_CFG               0x30
#define I3G4250D_REG_INT1_SRC               0x31
#define I3G4250D_REG_INT1_THS_XH            0x32
#define I3G4250D_REG_INT1_THS_XL            0x33
#define I3G4250D_REG_INT1_THS_YH            0x34
#define I3G4250D_REG_INT1_THS_YL            0x35
#define I3G4250D_REG_INT1_THS_ZH            0x36
#define I3G4250D_REG_INT1_THS_ZL            0x37
#define I3G4250D_REG_INT1_DURATION          0x38

#define I3G4250D_WHO_AM_I                   0xD3
#define I3G4250D_AUTO_INCR_BITMASK          0x80

#define I3G4250D_REG_CTRL_REG3_I2_DRDY      BIT(3) // Data ready on DRDY/INT2. Default value 0. (0: disable; 1: enable)
#define I3G4250D_REG_CTRL_REG3_H_LACTIVE    BIT(5) // Interrupt active configuration on INT1. Default value 0. (0: high; 1: low)
#define I3G4250D_REG_CTRL_REG3_I1_BOOT_EN   BIT(6) // I1_BOOT Boot status available on INT1. Default value 0. (0: disable; 1: enable)
#define I3G4250D_REG_CTRL_REG3_I1_INT1      BIT(7) // Interrupt enable on the INT1 pin. Default value 0. (0: disable; 1: enable)

#define I3G4250D_REG_CTRL_REG4_FS(fs)       ((fs) << 4)
#define LIS2DH12_FS_245dps                  0
#define LIS2DH12_FS_500dps                  1
#define LIS2DH12_FS_2000dps                 2

#define I3G4250D_REG_CTRL_REG5_BOOT         BIT(7) // Reboot memory content. Default value: 0 (0: normal mode; 1: reboot memory content)

#define I3G4250D_REG_INT1_DURATION_WAIT     BIT(7) // WAIT enable. Default value: 0 (0: disable; 1: enable)

#endif /* I3G4250D_DEF_H_ */
```

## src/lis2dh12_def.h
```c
#ifndef LIS2DH12_DEF_H_
#define LIS2DH12_DEF_H_


#define LIS2DH12_7BIT_ADDR                  0x19

#define LIS2DH12_REG_STATUS_REG_AUX         0x07
#define LIS2DH12_REG_OUT_TEMP_L             0x0C
#define LIS2DH12_REG_OUT_TEMP_H             0x0D
#define LIS2DH12_REG_WHO_AM_I               0x0F
#define LIS2DH12_REG_CTRL_REG0              0x1E
#define LIS2DH12_REG_TEMP_CFG_REG           0x1F
#define LIS2DH12_REG_CTRL_REG1              0x20
#define LIS2DH12_REG_CTRL_REG2              0x21
#define LIS2DH12_REG_CTRL_REG3              0x22
#define LIS2DH12_REG_CTRL_REG4              0x23
#define LIS2DH12_REG_CTRL_REG5              0x24
#define LIS2DH12_REG_CTRL_REG6              0x25
#define LIS2DH12_REG_REFERENCE              0x26
#define LIS2DH12_REG_STATUS                 0x27
#define LIS2DH12_REG_OUT_X_L                0x28
#define LIS2DH12_REG_OUT_X_H                0x29
#define LIS2DH12_REG_OUT_Y_L                0x2A
#define LIS2DH12_REG_OUT_Y_H                0x2B
#define LIS2DH12_REG_OUT_Z_L                0x2C
#define LIS2DH12_REG_OUT_Z_H                0x2D
#define LIS2DH12_REG_FIFO_CTRL_REG          0x2E
#define LIS2DH12_REG_FIFO_SRC_REG           0x2F
#define LIS2DH12_REG_INT1_CFG               0x30
#define LIS2DH12_REG_INT1_SRC               0x31
#define LIS2DH12_REG_INT1_THS               0x32
#define LIS2DH12_REG_INT1_DURATION          0x33
#define LIS2DH12_REG_INT2_CFG               0x34
#define LIS2DH12_REG_INT2_SRC               0x35
#define LIS2DH12_REG_INT2_THS               0x36
#define LIS2DH12_REG_INT2_DURATION          0x37
#define LIS2DH12_REG_CLICK_CFG              0x38
#define LIS2DH12_REG_CLICK_SRC              0x39
#define LIS2DH12_REG_CLICK_THS              0x3A
#define LIS2DH12_REG_TIME_LIMIT             0x3B
#define LIS2DH12_REG_TIME_LATENCY           0x3C
#define LIS2DH12_REG_TIME_WINDOW            0x3D
#define LIS2DH12_REG_ACT_THS                0x3E
#define LIS2DH12_REG_ACT_DUR                0x3F

#define LIS2DH12_WHO_AM_I                   0x33
#define LIS2DH12_AUTO_INCR                  0x80

#define LIS2DH12_REG_STATUS_REG_AUX_TDA         BIT(2) // Temperature new data available. Default value: 0
#define LIS2DH12_REG_STATUS_REG_AUX_TOR         BIT(6) // Temperature data overrun. Default value: 0

#define LIS2DH12_REG_CTRL_REG0_REQUIRED         BIT(4)
#define LIS2DH12_REG_CTRL_REG0_SDO_PU_DISC      BIT(7) // Disconnect SDO/SA0 pull-up. Default value: 00010000 (0: pull-up connected to SDO/SA0 pin; 1: pull-up disconnected to SDO/SA0 pin)

#define LIS2DH12_REG_TEMP_CFG_REG_TEMP_EN       (BIT(6) | BIT(7)) // Temperature sensor (T) enable. Default value: 00

#define LIS2DH12_REG_CTRL_REG1_XEN              BIT(0) // X-axis enable. Default value: 1
#define LIS2DH12_REG_CTRL_REG1_YEN              BIT(1) // Y-axis enable. Default value: 1
#define LIS2DH12_REG_CTRL_REG1_ZEN              BIT(2) // Z-axis enable. Default value: 1
#define LIS2DH12_REG_CTRL_REG1_LPEN             BIT(3) // Low-power mode enable. Default value: 0
#define LIS2DH12_REG_CTRL_REG1_ODR(odr)         ((odr) << 4)
#define LIS2DH12_ODR_POWER_DOWN                 0 // Power-down mode
#define LIS2DH12_ODR_1_HZ                       1 // HR / Normal / Low-power mode (1 Hz)
#define LIS2DH12_ODR_10_HZ                      2 // HR / Normal / Low-power mode (10 Hz)
#define LIS2DH12_ODR_25_HZ                      3 // HR / Normal / Low-power mode (25 Hz)
#define LIS2DH12_ODR_50_HZ                      4 // HR / Normal / Low-power mode (50 Hz)
#define LIS2DH12_ODR_100_HZ                     5 // HR / Normal / Low-power mode (100 Hz)
#define LIS2DH12_ODR_200_HZ                     6 // HR / Normal / Low-power mode (200 Hz)
#define LIS2DH12_ODR_400_HZ                     7 // HR/ Normal / Low-power mode (400 Hz)
#define LIS2DH12_ODR_LP_1620_HZ                 8 // Low-power mode (1.620 kHz)
#define LIS2DH12_ODR_1344_HZ_OR_LP_5376         9 // HR/ Normal (1.344 kHz); Low-power mode (5.376 kHz)

#define LIS2DH12_REG_CTRL_REG2_HPCLICK          BIT(2) // High-pass filter enabled for CLICK function. (0: filter bypassed; 1: filter enabled)

#define LIS2DH12_REG_CTRL_REG3_I1_OVERRUN       BIT(1) // FIFO overrun interrupt on INT1 pin. Default value: 0 (0: disable; 1: enable)
#define LIS2DH12_REG_CTRL_REG3_I1_WTM           BIT(2) // FIFO watermark interrupt on INT1 pin. Default value: 0 (0: disable; 1: enable)
#define LIS2DH12_REG_CTRL_REG3_I1_ZYXDA         BIT(4) // ZYXDA interrupt on INT1 pin. Default value: 0 (0: disable; 1: enable)
#define LIS2DH12_REG_CTRL_REG3_I1_IA2           BIT(5) // IA2 interrupt on INT1 pin. Default value: 0 (0: disable; 1: enable)
#define LIS2DH12_REG_CTRL_REG3_I1_IA1           BIT(6) // IA1 interrupt on INT1 pin. Default value: 0 (0: disable; 1: enable)
#define LIS2DH12_REG_CTRL_REG3_I1_CLICK         BIT(7) // CLICK interrupt on INT1 pin. Default value: 0 (0: disable; 1: enable)

#define LIS2DH12_REG_CTRL_REG4_SIM              BIT(0) // SPI serial interface mode selection. Default value: 0 (0: 4-wire interface; 1: 3-wire interface).
#define LIS2DH12_REG_CTRL_REG4_ST0              BIT(1) // Self test 0
#define LIS2DH12_REG_CTRL_REG4_ST1              BIT(2) // Self test 1
#define LIS2DH12_REG_CTRL_REG4_HR               BIT(3) // High-resolution mode enable.
#define LIS2DH12_REG_CTRL_REG4_FS(fs)           ((fs) << 4)
#define LIS2DH12_FS_2g                          0 // Full-scale ±2 g
#define LIS2DH12_FS_4g                          1 // Full-scale ±4 g
#define LIS2DH12_FS_8g                          2 // Full-scale ±8 g
#define LIS2DH12_FS_16g                         3 // Full-scale±16 g
#define LIS2DH12_REG_CTRL_REG4_BLE              BIT(6) // Big/Little Endian data selection. Default value: 0. (0: data LSb at lower address; 1: data MSb at lower address) The BLE function can be activated only in high-resolution mode 
#define LIS2DH12_REG_CTRL_REG4_BDU              BIT(7) // Block data update. Default value: 0. (0: continuous update; 1: output registers not updated until MSB and LSB have been read)

#define LIS2DH12_REG_CTRL_REG5_BOOT             BIT(7) // Reboot memory content. Default value: 0 (0: normal mode; 1: reboot memory content)

#define LIS2DH12_REG_CTRL_REG6_INT_ACTIVE_LOW   BIT(1) // INT_POLARITY INT1 and INT2 pin polarity. Default value: 0 (0: active-high; 1: active-low)
#define LIS2DH12_REG_CTRL_REG6_I2_ACT           BIT(3) // Enable activity interrupt on INT2 pin. Default value: 0 (0: disabled; 1: enabled)
#define LIS2DH12_REG_CTRL_REG6_I2_BOOT_EN       BIT(4) // I2_BOOT Enable boot on INT2 pin. Default value: 0 (0: disabled; 1: enabled)
#define LIS2DH12_REG_CTRL_REG6_I2_IA2           BIT(5) // Enable interrupt 2 function on INT2 pin. Default value: 0 (0: function disabled; 1: function enabled)
#define LIS2DH12_REG_CTRL_REG6_I2_IA1           BIT(6) // Enable interrupt 1 function on INT2 pin. Default value: 0 (0: function disabled; 1: function enabled)
#define LIS2DH12_REG_CTRL_REG6_I2_CLICK         BIT(7) // Click interrupt on INT2 pin. Default value: 0 (0: disabled; 1: enabled)

#define LIS2DH12_REG_CLICK_CFG_XS               BIT(0) // Enable interrupt single-click on X-axis. Default value: 0 (0: disable interrupt request; 1: enable interrupt request on measured accel. value higher than preset threshold)
#define LIS2DH12_REG_CLICK_CFG_XD               BIT(1) // Enable interrupt double-click on X-axis. Default value: 0 (0: disable interrupt request; 1: enable interrupt request on measured accel. value higher than preset threshold)
#define LIS2DH12_REG_CLICK_CFG_YS               BIT(2) // Enable interrupt single-click on Y-axis. Default value: 0 (0: disable interrupt request; 1: enable interrupt request on measured accel. value higher than preset threshold)
#define LIS2DH12_REG_CLICK_CFG_YD               BIT(3) // Enable interrupt double-click on Y-axis. Default value: 0 (0: disable interrupt request; 1: enable interrupt request on measured accel. value higher than preset threshold)
#define LIS2DH12_REG_CLICK_CFG_ZS               BIT(4) // Enable interrupt single-click on Z-axis. Default value: 0 (0: disable interrupt request; 1: enable interrupt request on measured accel. value higher than preset threshold)
#define LIS2DH12_REG_CLICK_CFG_ZD               BIT(5) // Enable interrupt double-click on Z-axis. Default value: 0 (0: disable interrupt request; 1: enable interrupt request on measured accel. value higher than preset threshold)

#define LIS2DH12_REG_CLICK_THS_LIR_CLICK        BIT(7) // If the LIR_Click bit is not set, the interrupt is kept high for the duration of the latency window. If the LIR_Click bit is set, the interrupt is kept high until the CLICK_SRC (39h) register is read.

#define LIS2DH12_MODE_HIGH_RESOLUTION           0x00
#define LIS2DH12_MODE_NORMAL                    0x01
#define LIS2DH12_MODE_LOW_POWER                 0x02

#endif /* LIS2DH12_DEF_H_ */
```

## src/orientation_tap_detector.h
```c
/*
 * Copyright (c) 2020 Avnet Asia Pte. Ltd.
 *
 * SPDX-License-Identifier: LicenseRef-BSD-3-Clause
 */
 
#ifndef ORIENTATION_TAP_DETECTOR_H_
#define ORIENTATION_TAP_DETECTOR_H_

/**@file
 *
 * @brief   Orientation and tap detector module.
 *
 * Module that uses STM LIS2DH12 accelerometer to detect device's orientation 
 * and tap event.
 */

#define GET_ORIENTATION_XYZ     0


/**@brief Orientation states. */
/* sequence is based on the bitpos provided in LIS2DH12_REG_INT1_SRC */
typedef enum {
    ORIENTATION_NOT_KNOWN,
    ORIENTATION_LANDSCAPE,
    ORIENTATION_REVERSE_LANDSCAPE,
    ORIENTATION_REVERSE_PORTRAIT,
    ORIENTATION_PORTRAIT,
    ORIENTATION_FACE_DOWN,
    ORIENTATION_FACE_UP,
}orientation_state_t;

/**
 * @brief Defines event parameters provided to the application.
 */
typedef struct {
    orientation_state_t orientation;
    bool                tap_detected;
#if defined (GET_ORIENTATION_XYZ) && (GET_ORIENTATION_XYZ > 0)
    int16_t               x;
    int16_t               y;
    int16_t               z;
#endif
} orientation_tap_event_t;

/**@brief Function to get informed of orientation change or tap detection. */
typedef void (*orientation_tap_handler_t)(
                                orientation_tap_event_t orientation_tap_event);


/**@brief Initializes and start the orientation tap detector function.
 *
 * @param[in] work_q Workqueue where processing is done and event_handler
 *                   will be called.
 * @param[in] event_handler Callback function to call on orientation change or 
 *                          tap detection.
 *
 * @retval 0 If the operation was successful.
 *           Otherwise, a (negative) error code is returned.
 *
 */
int orientation_tap_detector_init_and_start(struct k_work_q *work_q, 
                                    orientation_tap_handler_t event_handler);

/**@brief Stopped and uninitializes the orientation tap detector function. */
void orientation_tap_detector_stop_and_unint(void);


#endif /* ORIENTATION_TAP_DETECTOR_H_ */
```

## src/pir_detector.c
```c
/*
 * Copyright (c) 2020 Avnet Asia Pte. Ltd.
 *
 * SPDX-License-Identifier: LicenseRef-BSD-3-Clause
 */

#include <zephyr.h>
#include <device.h>
#include <errno.h>
#include <drivers/i2c.h>
#include <drivers/gpio.h>

#include "te23142771_def.h"
#include "pir_detector.h"


#include <logging/log.h>
LOG_MODULE_REGISTER(pir, LOG_LEVEL_INF);

#define U5_I2C_NODE                 DT_ALIAS(sens_i2c)
#define U5_I2C_DEVICE               DT_LABEL(U5_I2C_NODE)

#define U5_EVENT_OUT_NODE           DT_ALIAS(ard_d0)
#define U5_EVENT_OUT_PORT_DEVICE    DT_GPIO_LABEL(U5_EVENT_OUT_NODE, gpios)
#define U5_EVENT_OUT_PIN_NUMBER     DT_GPIO_PIN(U5_EVENT_OUT_NODE, gpios)


static const struct device      *u5_i2c_dev = NULL;
static const struct device      *u5_event_out_port_dev = NULL;
static struct gpio_callback     u5_event_out_cb;

static struct k_work_q          *caller_work_q = NULL;
static struct k_delayed_work    event_out_detect_work;
static struct k_delayed_work    observe_cool_off_work;

static pir_event_handler_t      handler = NULL;

#define PIR_DETECT_COOL_OFF_PERIOD_SEC  2

static uint32_t    pir_on;
static uint32_t    prev_pir_on;

static void analyze_data(void)
{
    if ((prev_pir_on != pir_on) && ((prev_pir_on == 0) || (pir_on == 0))) {
        bool pir_detected = (prev_pir_on == 0);

        LOG_DBG("U5 2314277-1 Ambimate PIR/MOTION %s %d %d.\r\n", 
                        pir_detected ? "ON" : "OFF", prev_pir_on, pir_on);
        prev_pir_on = pir_on;
        if (handler != NULL) {
            handler(pir_detected);
        }
    }
}

static void event_out_detect_work_fn(struct k_work *work)
{
    int err;
    uint8_t reg_value;

    if (pir_on > 0) {
        k_delayed_work_cancel(&observe_cool_off_work);
        pir_on++;
        if (pir_on == 0) {
            pir_on = 1;
        }
    } else {
        pir_on++;
    }
    err = k_delayed_work_submit_to_queue(caller_work_q, &observe_cool_off_work, 
                                    K_SECONDS(PIR_DETECT_COOL_OFF_PERIOD_SEC));
    if (err != 0) {
        LOG_ERR("k_delayed_work_submit_to_queue(observe_cool_off) "
                        "failed (err: %d)", err);
    }

    err = i2c_reg_read_byte(u5_i2c_dev, TE_2314277_1_7BIT_ADDR, 
                            TE_2314277_1_REG_STATUS, &reg_value);
    if (err != 0) {
        LOG_ERR("Fail to read TE_2314277_1_REG_STATUS");
        return;
    }
    LOG_DBG("TE_2314277_1_REG_STATUS 0x%02x", reg_value);

    analyze_data();
}

static void observe_cool_off_work_fn(struct k_work *work)
{
    pir_on = 0;
    analyze_data();
}

static void u5_event_out_asserted(const struct device *gpiob, 
                                    struct gpio_callback *cb, uint32_t pins)
{
    LOG_DBG("u5_event_out_asserted");
    int err = k_delayed_work_submit_to_queue(caller_work_q, 
                                        &event_out_detect_work, K_NO_WAIT);
    if (err != 0) {
        LOG_ERR("k_delayed_work_submit_to_queue(event_out_detect) "
                        "failed (err: %d)", err);
    }
}

static void deconfig_int_pins(void)
{
    if (u5_event_out_port_dev != NULL) {
        (void) gpio_pin_interrupt_configure(u5_event_out_port_dev, 
                                    U5_EVENT_OUT_PIN_NUMBER, GPIO_INT_DISABLE);
        (void) gpio_remove_callback(u5_event_out_port_dev, &u5_event_out_cb);
        (void) gpio_pin_configure(u5_event_out_port_dev, 
                                    U5_EVENT_OUT_PIN_NUMBER, GPIO_DISCONNECTED);
    }
}

static int config_int_pins(void)
{
    int err;

    u5_event_out_port_dev = device_get_binding(U5_EVENT_OUT_PORT_DEVICE);
    if (u5_event_out_port_dev == NULL) {
        LOG_ERR("%s pin not found",  DT_PROP(U5_EVENT_OUT_NODE, label));
        return -ENODEV;
    }

    err = gpio_pin_configure(u5_event_out_port_dev, U5_EVENT_OUT_PIN_NUMBER, 
                                GPIO_INPUT | GPIO_PULL_DOWN);
    if (err != 0) {
        LOG_ERR("%s pin configure failed %d", 
                    DT_PROP(U5_EVENT_OUT_NODE, label), err);
        goto cleanup;
    }
    gpio_init_callback(&u5_event_out_cb, u5_event_out_asserted, 
                        BIT(U5_EVENT_OUT_PIN_NUMBER));
    err = gpio_add_callback(u5_event_out_port_dev, &u5_event_out_cb);
    if (err != 0) {
        LOG_ERR("%s pin add callback failed %d", 
                    DT_PROP(U5_EVENT_OUT_NODE, label), err);
        goto cleanup;
    }
    err = gpio_pin_interrupt_configure(u5_event_out_port_dev, 
                            U5_EVENT_OUT_PIN_NUMBER, GPIO_INT_EDGE_TO_ACTIVE);
    if (err != 0) {
        LOG_ERR("%s pin interrupt configure failed %d", 
                    DT_PROP(U5_EVENT_OUT_NODE, label), err);
        goto cleanup;
    }
    LOG_DBG("U5 EVENT OUT (%s pin) configured", 
                DT_PROP(U5_EVENT_OUT_NODE, label));

    return 0;

cleanup:
    deconfig_int_pins();
    return err;
}

int pir_detector_init_and_start(struct k_work_q *work_q, 
                                pir_event_handler_t event_handler)
{
    int err;
    uint8_t reg_value;

    if ((work_q == NULL) || (event_handler == NULL)) {
        return -EINVAL;
    }

    if (caller_work_q != NULL) {
        /* already init and started */
        return -EALREADY;
    }

    err = config_int_pins();
    if (err != 0) {
        return err;
    }

    caller_work_q = work_q;
    handler = event_handler;

    k_delayed_work_init(&event_out_detect_work, event_out_detect_work_fn);
    k_delayed_work_init(&observe_cool_off_work, observe_cool_off_work_fn);

    u5_i2c_dev = device_get_binding(U5_I2C_DEVICE);
    if (u5_i2c_dev == NULL) {
        LOG_ERR("TE 2314277-1 not found");
        err = -ENODEV;
        goto cleanup;
    }

    err = i2c_reg_read_byte(u5_i2c_dev, TE_2314277_1_7BIT_ADDR, 
                            TE_2314277_1_REG_OPTIONAL_SENSORS, &reg_value);
    if (err != 0) {
        LOG_ERR("Fail to read TE_2314277_1_REG_OPTIONAL_SENSORS %d", err);
        goto cleanup;
    }
    /* TE sensor installed on AVT9152 has no optional sensors */
    if (reg_value != TE_2314277_1_OPTIONAL_SENSORS_NONE) {
        LOG_ERR("Unexpected TE_2314277_1_OPTIONAL_SENSORS_NONE value 0x%02x", 
                    reg_value);
        err = -ENOTSUP;
        goto cleanup;
    }

    /* to clear event out */
    err = i2c_reg_read_byte(u5_i2c_dev, TE_2314277_1_7BIT_ADDR, 
                            TE_2314277_1_REG_STATUS, &reg_value);
    if (err != 0) {
        LOG_ERR("Fail to read TE_2314277_1_REG_STATUS");
        goto cleanup;
    }

    return 0;

cleanup:
    handler = NULL;
    caller_work_q = NULL;
    deconfig_int_pins();
    return err;
}

void pir_detector_stop_and_unit(void)
{
    if (caller_work_q == NULL) {
        /* not init and started */
        return;
    }

    handler = NULL;
    caller_work_q = NULL;
    deconfig_int_pins();
}
```
